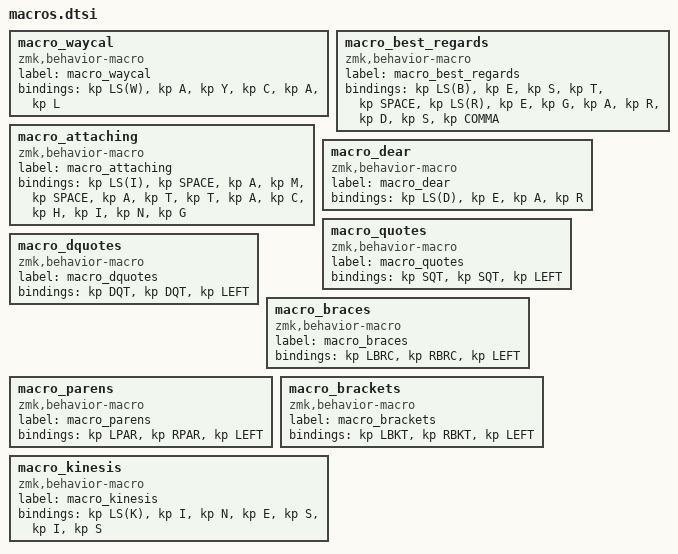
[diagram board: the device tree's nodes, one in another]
macro_waycal: macro_waycal{
compatible = "zmk,behavior-macro";
label = "macro_waycal";
#binding-cells = <0>;
bindings = <&kp LS(W)>, <&kp A>, <&kp Y>, <&kp C>, <&kp A>, <&kp L>;
};
macro_best_regards: macro_best_regards{
compatible = "zmk,behavior-macro";
label = "macro_best_regards";
#binding-cells = <0>;
bindings = <&kp LS(B)>, <&kp E>, <&kp S>, <&kp T>, <&kp SPACE>, <&kp LS(R)>, <&kp E>, <&kp G>, <&kp A>, <&kp R>, <&kp D>, <&kp S>, <&kp COMMA>;
};
macro_attaching: macro_attaching{
compatible = "zmk,behavior-macro";
label = "macro_attaching";
#binding-cells = <0>;
bindings = <&kp LS(I)>, <&kp SPACE>, <&kp A>, <&kp M>, <&kp SPACE>, <&kp A>, <&kp T>, <&kp T>, <&kp A>, <&kp C>, <&kp H>, <&kp I>, <&kp N>, <&kp G>;
};
macro_dear: macro_dear{
compatible = "zmk,behavior-macro";
label = "macro_dear";
#binding-cells = <0>;
bindings = <&kp LS(D)>, <&kp E>, <&kp A>, <&kp R>;
};
macro_quotes: macro_quotes{
compatible = "zmk,behavior-macro";
label = "macro_quotes";
#binding-cells = <0>;
bindings = <&kp SQT>, <&kp SQT>, <&kp LEFT>;
};
macro_dquotes: macro_dquotes{
compatible = "zmk,behavior-macro";
label = "macro_dquotes";
#binding-cells = <0>;
bindings = <&kp DQT>, <&kp DQT>, <&kp LEFT>;
};
macro_braces: macro_braces{
compatible = "zmk,behavior-macro";
label = "macro_braces";
#binding-cells = <0>;
bindings = <&kp LBRC>, <&kp RBRC>, <&kp LEFT>;
};
macro_parens: macro_parens{
compatible = "zmk,behavior-macro";
label = "macro_parens";
#binding-cells = <0>;
bindings = <&kp LPAR>, <&kp RPAR>, <&kp LEFT>;
};
macro_brackets: macro_brackets{
compatible = "zmk,behavior-macro";
label = "macro_brackets";
#binding-cells = <0>;
bindings = <&kp LBKT>, <&kp RBKT>, <&kp LEFT>;
};
macro_kinesis: macro_kinesis{
compatible = "zmk,behavior-macro";
label = "macro_kinesis";
#binding-cells = <0>;
bindings = <&kp LS(K)>, <&kp I>, <&kp N>, <&kp E>, <&kp S>, <&kp I>, <&kp S>;
};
